# STM32MP151x register map
File version: 1.0
Registers are 32-bit, read-write, reset 0x0 unless marked. A register's access mark holds for its fields unless they carry their own. Offsets are from the block's base; [hi:lo] are bit positions.

## SPI1
Base 0x44004000
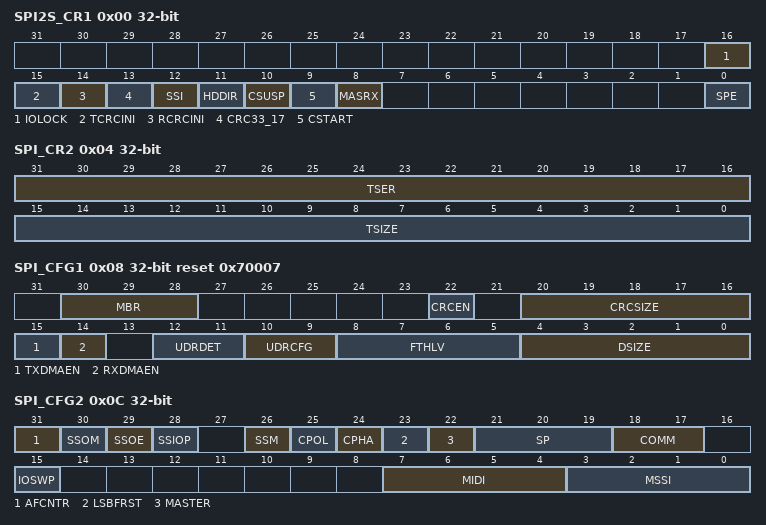
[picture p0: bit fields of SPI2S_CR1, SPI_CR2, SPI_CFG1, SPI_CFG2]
0x00 SPI2S_CR1 access per field — SPI/I2S control register 1
  [16] IOLOCK rw, [15] TCRCINI rw, [14] RCRCINI rw, [13] CRC33_17 rw, [12] SSI rw, [11] HDDIR rw, [10] CSUSP wo, [9] CSTART rw, [8] MASRX rw, [0] SPE rw
0x04 SPI_CR2 — SPI control register 2
  [31:16] TSER, [15:0] TSIZE
0x08 SPI_CFG1 reset 0x70007 — Content of this register is write protected when SPI is enabled
  [30:28] MBR, [22] CRCEN, [20:16] CRCSIZE, [15] TXDMAEN, [14] RXDMAEN, [12:11] UDRDET, [10:9] UDRCFG, [8:5] FTHLV, [4:0] DSIZE
0x0C SPI_CFG2 — The content of this register is write protected when SPI is enabled or IOLOCK bit is set at SPI2S_CR1 register.
  [31] AFCNTR, [30] SSOM, [29] SSOE, [28] SSIOP, [26] SSM, [25] CPOL, [24] CPHA, [23] LSBFRST, [22] MASTER, [21:19] SP, [18:17] COMM, [15] IOSWP, [7:4] MIDI, [3:0] MSSI
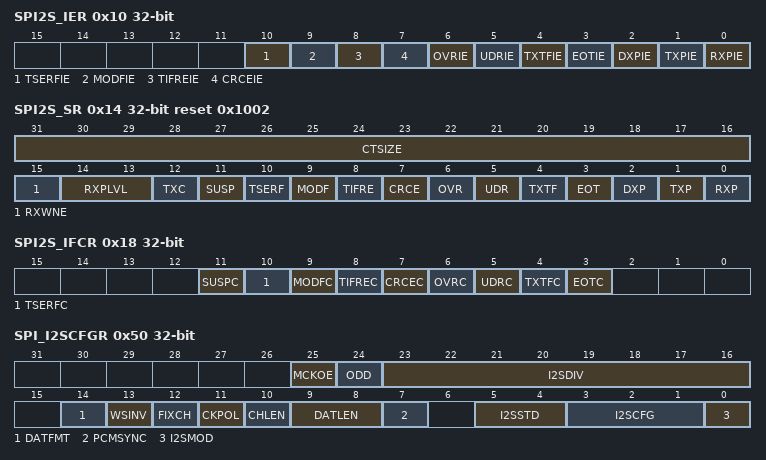
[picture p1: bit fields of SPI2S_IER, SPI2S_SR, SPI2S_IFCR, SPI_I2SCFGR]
0x10 SPI2S_IER — SPI/I2S interrupt enable register
  [10] TSERFIE, [9] MODFIE, [8] TIFREIE, [7] CRCEIE, [6] OVRIE, [5] UDRIE, [4] TXTFIE, [3] EOTIE, [2] DXPIE, [1] TXPIE, [0] RXPIE
0x14 SPI2S_SR ro reset 0x1002 — SPI/I2S status register
  [31:16] CTSIZE, [15] RXWNE, [14:13] RXPLVL, [12] TXC, [11] SUSP, [10] TSERF, [9] MODF, [8] TIFRE, [7] CRCE, [6] OVR, [5] UDR, [4] TXTF, [3] EOT, [2] DXP, [1] TXP, [0] RXP
0x18 SPI2S_IFCR wo — SPI/I2S interrupt/status flags clear register
  [11] SUSPC, [10] TSERFC, [9] MODFC, [8] TIFREC, [7] CRCEC, [6] OVRC, [5] UDRC, [4] TXTFC, [3] EOTC
0x20 SPI2S_TXDR wo — SPI/I2S transmit data register
0x30 SPI2S_RXDR ro — SPI/I2S receive data register
0x40 SPI_CRCPOLY reset 0x107 — SPI polynomial register
0x44 SPI_TXCRC ro — SPI transmitter CRC register
0x48 SPI_RXCRC ro — SPI receiver CRC register
0x4C SPI_UDRDR — SPI underrun data register
0x50 SPI_I2SCFGR — All documented bits in this register must be configured when the I2S is disabled (SPE = 0).These bits are not used in SPI mode except for I2SMOD which needs to be set to 0 in SPI mode.
  [25] MCKOE, [24] ODD, [23:16] I2SDIV, [14] DATFMT, [13] WSINV, [12] FIXCH, [11] CKPOL, [10] CHLEN, [9:8] DATLEN, [7] PCMSYNC, [5:4] I2SSTD, [3:1] I2SCFG, [0] I2SMOD
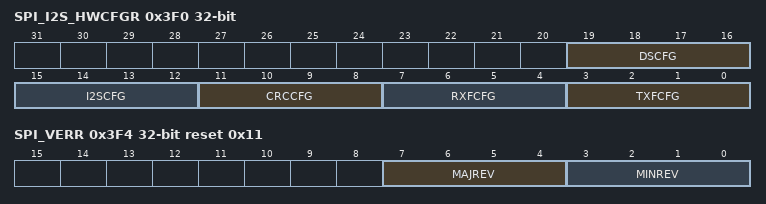
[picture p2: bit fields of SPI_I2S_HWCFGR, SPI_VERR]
0x3F0 SPI_I2S_HWCFGR ro — SPI/I2S hardware configuration register
  [19:16] DSCFG, [15:12] I2SCFG, [11:8] CRCCFG, [7:4] RXFCFG, [3:0] TXFCFG
0x3F4 SPI_VERR ro reset 0x11 — SPI/I2S version register
  [7:4] MAJREV, [3:0] MINREV
0x3F8 SPI_IPIDR ro reset 0x130022 — SPI/I2S identification register
  [31:0] ID
0x3FC SPI_SIDR ro reset 0xA3C5DD01 — SPI/I2S size identification register
  [31:0] SID

## SPI2
Base 0x4000B000
Same registers: SPI3 0x4000C000, SPI4 0x44005000, SPI5 0x44009000, SPI6 0x5C001000
Registers as SPI1, without SPI2S_CR1, SPI2S_IER, SPI2S_SR, SPI2S_IFCR, SPI2S_TXDR, SPI2S_RXDR; these are added or differ:
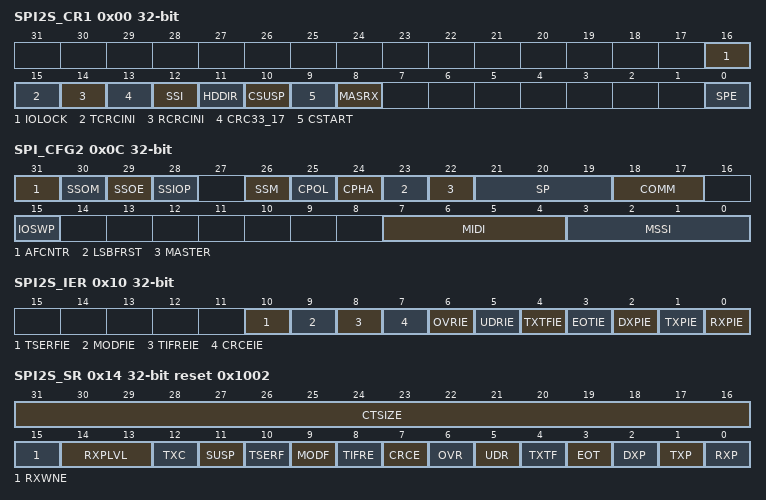
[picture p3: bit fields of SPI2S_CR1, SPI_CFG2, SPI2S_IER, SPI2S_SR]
0x00 SPI2S_CR1 access per field — SPI/I2S control register 1
  [16] IOLOCK rw, [15] TCRCINI rw, [14] RCRCINI rw, [13] CRC33_17 rw, [12] SSI rw, [11] HDDIR rw, [10] CSUSP wo, [9] CSTART rw, [8] MASRX rw, [0] SPE rw
0x0C SPI_CFG2 — The content of this register is write protected when SPI is enabled or IOLOCK bit is set at SPI2S_CR1 register.
  [31] AFCNTR, [30] SSOM, [29] SSOE, [28] SSIOP, [26] SSM, [25] CPOL, [24] CPHA, [23] LSBFRST, [22] MASTER, [21:19] SP, [18:17] COMM, [15] IOSWP, [7:4] MIDI, [3:0] MSSI
0x10 SPI2S_IER — SPI/I2S interrupt enable register
  [10] TSERFIE, [9] MODFIE, [8] TIFREIE, [7] CRCEIE, [6] OVRIE, [5] UDRIE, [4] TXTFIE, [3] EOTIE, [2] DXPIE, [1] TXPIE, [0] RXPIE
0x14 SPI2S_SR ro reset 0x1002 — SPI/I2S status register
  [31:16] CTSIZE, [15] RXWNE, [14:13] RXPLVL, [12] TXC, [11] SUSP, [10] TSERF, [9] MODF, [8] TIFRE, [7] CRCE, [6] OVR, [5] UDR, [4] TXTF, [3] EOT, [2] DXP, [1] TXP, [0] RXP
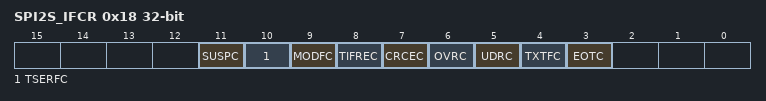
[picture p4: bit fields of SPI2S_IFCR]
0x18 SPI2S_IFCR wo — SPI/I2S interrupt/status flags clear register
  [11] SUSPC, [10] TSERFC, [9] MODFC, [8] TIFREC, [7] CRCEC, [6] OVRC, [5] UDRC, [4] TXTFC, [3] EOTC
0x20 SPI2S_TXDR wo — SPI/I2S transmit data register
0x30 SPI2S_RXDR ro — SPI/I2S receive data register
